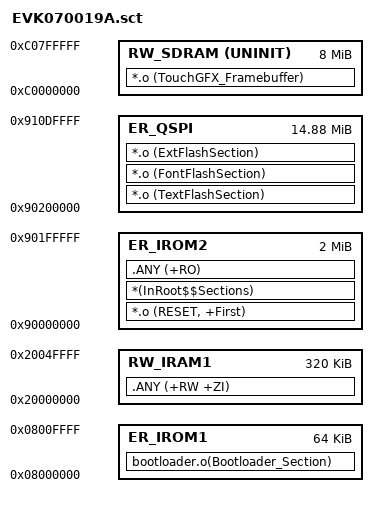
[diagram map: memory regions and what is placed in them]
; *************************************************************
; *** Scatter-Loading Description File generated by uVision ***
; *************************************************************
LR_IROM1 0x08000000 0x00010000  {    ; load region size_region
  ER_IROM1 0x08000000 0x00010000  {  ; load address = execution address
    bootloader.o(Bootloader_Section)
  }
}

LR_IROM2 0x90000000 0x00200000  {    ; load region size_region
  ER_IROM2 0x90000000 0x00200000  {  ; load address = execution address
   *.o (RESET, +First)
   *(InRoot$$Sections)
   .ANY (+RO)
  }
   RW_IRAM1 0x20000000 0x00050000  {  ; RW data
  .ANY (+RW +ZI)
  }
  RW_SDRAM 0xC0000000 UNINIT 0x00800000 {
   *.o (TouchGFX_Framebuffer)
  }
}

LR_QSPI 0x90200000 0x00EE0000  {    ; load region size_region
  ER_QSPI 0x90200000 0x00EE0000 {
   *.o (TextFlashSection)
   *.o (FontFlashSection)
   *.o (ExtFlashSection)
  }
}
